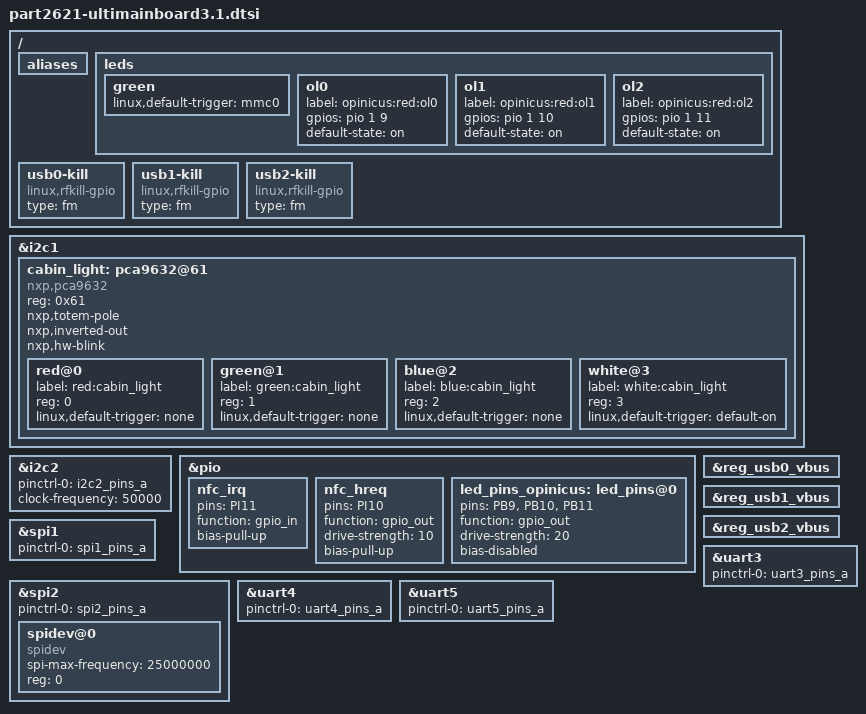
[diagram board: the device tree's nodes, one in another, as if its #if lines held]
/*
 * Copyright 2015 - Ultimaker B.V.
 * Author Olliver Schinagl <o.schinagl@ultimaker.com>
 *
 * This file is dual-licensed: you can use it either under the terms
 * of the GPL or the X11 license, at your option. Note that this dual
 * licensing only applies to this file, and not this project as a
 * whole.
 *
 *  a) This file is free software; you can redistribute it and/or
 *     modify it under the terms of the GNU General Public License as
 *     published by the Free Software Foundation; either version 2 of the
 *     License, or (at your option) any later version.
 *
 *     This file is distributed in the hope that it will be useful,
 *     but WITHOUT ANY WARRANTY; without even the implied warranty of
 *     MERCHANTABILITY or FITNESS FOR A PARTICULAR PURPOSE.  See the
 *     GNU General Public License for more details.
 *
 * Or, alternatively,
 *
 *  b) Permission is hereby granted, free of charge, to any person
 *     obtaining a copy of this software and associated documentation
 *     files (the "Software"), to deal in the Software without
 *     restriction, including without limitation the rights to use,
 *     copy, modify, merge, publish, distribute, sublicense, and/or
 *     sell copies of the Software, and to permit persons to whom the
 *     Software is furnished to do so, subject to the following
 *     conditions:
 *
 *     The above copyright notice and this permission notice shall be
 *     included in all copies or substantial portions of the Software.
 *
 *     THE SOFTWARE IS PROVIDED "AS IS", WITHOUT WARRANTY OF ANY KIND,
 *     EXPRESS OR IMPLIED, INCLUDING BUT NOT LIMITED TO THE WARRANTIES
 *     OF MERCHANTABILITY, FITNESS FOR A PARTICULAR PURPOSE AND
 *     NONINFRINGEMENT. IN NO EVENT SHALL THE AUTHORS OR COPYRIGHT
 *     HOLDERS BE LIABLE FOR ANY CLAIM, DAMAGES OR OTHER LIABILITY,
 *     WHETHER IN AN ACTION OF CONTRACT, TORT OR OTHERWISE, ARISING
 *     FROM, OUT OF OR IN CONNECTION WITH THE SOFTWARE OR THE USE OR
 *     OTHER DEALINGS IN THE SOFTWARE.
 */
#ifdef IMX6DL_ULTIMAKER
// #include "msc-sm2-imx6dl.dtsi"
#else
// #include "jedi-common.dts"
#endif
/ {
	aliases {
//		serial1 = &uart4;
	};

	leds {
		green {
			linux,default-trigger = "mmc0";
		};

#ifndef IMX6DL_ULTIMAKER
		ol0 {
			label = "opinicus:red:ol0";
			gpios = <&pio 1 9 GPIO_ACTIVE_HIGH>;
			default-state = "on";
		};

		ol1 {
			label = "opinicus:red:ol1";
			gpios = <&pio 1 10 GPIO_ACTIVE_HIGH>;
			default-state = "on";
		};

		ol2 {
			label = "opinicus:red:ol2";
			gpios = <&pio 1 11 GPIO_ACTIVE_HIGH>;
			default-state = "on";
		};

#endif
	};

	usb0-kill {
		compatible = "linux,rfkill-gpio";
		type = "fm";
#ifdef IMX6DL_ULTIMAKER
#else
		shutdown-gpios = <&pio 2 17 GPIO_ACTIVE_HIGH>;
#endif
	};

	usb1-kill {
		compatible = "linux,rfkill-gpio";
		type = "fm";
#ifdef IMX6DL_ULTIMAKER
#else
		shutdown-gpios = <&pio 7 6 GPIO_ACTIVE_HIGH>;
#endif
	};

	usb2-kill {
		compatible = "linux,rfkill-gpio";
		type = "fm";
#ifdef IMX6DL_ULTIMAKER
#else
		shutdown-gpios = <&pio 7 3 GPIO_ACTIVE_HIGH>;
#endif
	};
};

&i2c1 {
	cabin_light: pca9632@61 {
		compatible = "nxp,pca9632";
		#address-cells = <1>;
		#size-cells = <0>;
		reg = <0x61>;
		nxp,totem-pole;
		nxp,inverted-out;
		nxp,hw-blink;

		red@0 {
			label = "red:cabin_light";
			reg = <0>;
			linux,default-trigger = "none";
		};

		green@1 {
			label = "green:cabin_light";
			reg = <1>;
			linux,default-trigger = "none";
		};

		blue@2 {
			label = "blue:cabin_light";
			reg = <2>;
			linux,default-trigger = "none";
		};

		white@3 {
			label = "white:cabin_light";
			reg = <3>;
			linux,default-trigger = "default-on";
		};
	};
};

#ifndef IMX6DL_ULTIMAKER

&i2c2 {
	pinctrl-names = "default";
	pinctrl-0 = <&i2c2_pins_a>;
	clock-frequency = <50000>;
	status = "okay";
};

&pio {
	nfc_irq: nfc_irq {
		pins = "PI11";
		function = "gpio_in";
		bias-pull-up;
	};

	nfc_hreq: nfc_hreq {
		pins = "PI10";
		function = "gpio_out";
		drive-strength = <10>;
		bias-pull-up;
	};

	led_pins_opinicus: led_pins@0 {
		pins = "PB9", "PB10", "PB11";
		function = "gpio_out";
		drive-strength = <20>;
		bias-disabled;
	};
};

&reg_usb0_vbus {
	/delete-property/ gpio;
};

&reg_usb1_vbus {
	/delete-property/ gpio;
};

&reg_usb2_vbus {
	/delete-property/ gpio;
};

&spi1 {
	pinctrl-names = "default";
	pinctrl-0 = <&spi1_pins_a>;
	status = "okay";
};

&spi2 {
	pinctrl-names = "default";
	pinctrl-0 = <&spi2_pins_a>;
	status = "okay";

	spidev@0 {
		compatible = "spidev";
		spi-max-frequency = <25000000>;
		reg = <0>;
	};
};

&uart3 {
	pinctrl-names = "default";
	pinctrl-0 = <&uart3_pins_a>;
	status = "okay";
};

&uart4 {
	pinctrl-names = "default";
	pinctrl-0 = <&uart4_pins_a>;
	status = "okay";
};

&uart5 {
	pinctrl-names = "default";
	pinctrl-0 = <&uart5_pins_a>;
	status = "okay";
};
#endif
